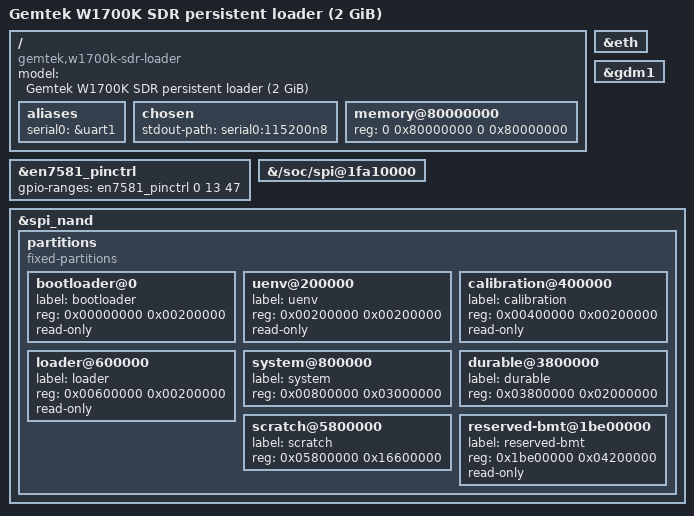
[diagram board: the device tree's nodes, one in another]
// SPDX-License-Identifier: (GPL-2.0-only OR BSD-2-Clause)
/dts-v1/;

// Memory that ATF, the NPU firmware and the QDMA rings own; Linux keeps these too.
/memreserve/ 0x80000000 0x00200000;
/memreserve/ 0x84000000 0x00a00000;
/memreserve/ 0x87000000 0x02000000;
/memreserve/ 0x89000000 0x01000000;

#include "en7581.dtsi"

/ {
	model = "Gemtek W1700K SDR persistent loader (2 GiB)";
	compatible = "gemtek,w1700k-sdr-loader", "airoha,an7581", "airoha,en7581";
	aliases {
		serial0 = &uart1;
	};
	chosen {
		stdout-path = "serial0:115200n8";
	};
	memory@80000000 {
		device_type = "memory";
		reg = <0 0x80000000 0 0x80000000>;
	};
};

&en7581_pinctrl {
	gpio-ranges = <&en7581_pinctrl 0 13 47>;
};

// Ethernet for TFTP and NAND for booting. PCIe and I2C are left to Linux.
&eth { status = "okay"; };
&gdm1 { status = "okay"; };

&{/soc/spi@1fa10000} { status = "okay"; };

&spi_nand {
	partitions {
		compatible = "fixed-partitions";
		#address-cells = <1>;
		#size-cells = <1>;

		// >>> generated by platform/partitions.py; edit that, not this
		// Vendor-logical offsets; BBT shift + BMT substitution exactly once.
		bootloader@0 {
			label = "bootloader";
			reg = <0x00000000 0x00200000>;
			read-only;
		};

		uenv@200000 {
			label = "uenv";
			reg = <0x00200000 0x00200000>;
			read-only;
		};

		calibration@400000 {
			label = "calibration";
			reg = <0x00400000 0x00200000>;
			read-only;
		};

		loader@600000 {
			label = "loader";
			reg = <0x00600000 0x00200000>;
			read-only;
		};

		system@800000 {
			label = "system";
			reg = <0x00800000 0x03000000>;
		};

		durable@3800000 {
			label = "durable";
			reg = <0x03800000 0x02000000>;
		};

		scratch@5800000 {
			label = "scratch";
			reg = <0x05800000 0x16600000>;
		};

		reserved-bmt@1be00000 {
			label = "reserved-bmt";
			reg = <0x1be00000 0x04200000>;
			read-only;
		};
		// <<< end generated partition table
	};
};
